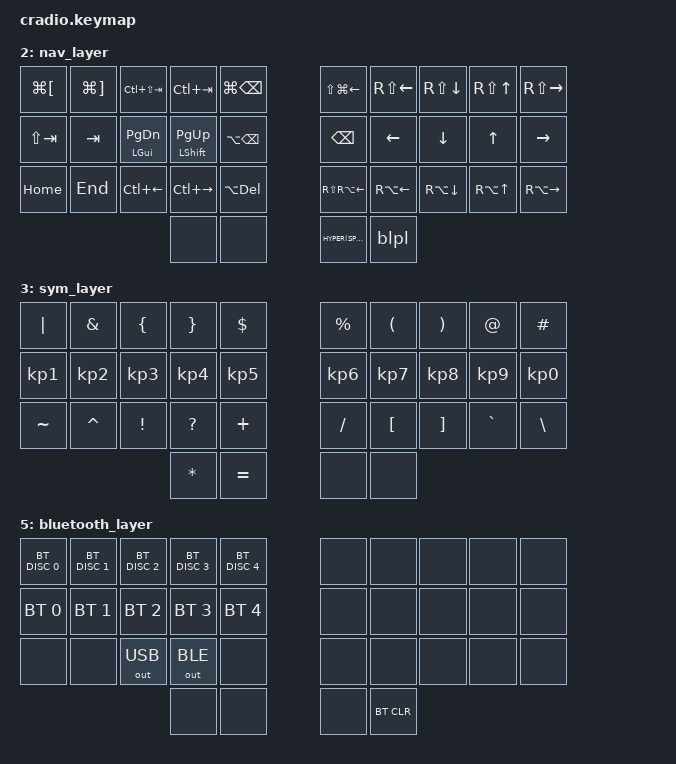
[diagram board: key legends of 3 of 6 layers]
#include <behaviors.dtsi>
#include <dt-bindings/zmk/keys.h>
#include <dt-bindings/zmk/bt.h>
#include <dt-bindings/zmk/outputs.h>

// Home row mods macro
#define HRML(k1, k2, k3) &hrm LALT k1  &hrm LGUI k2  &hrm LSHFT k3
#define HRMR(k1, k2, k3) &hrm RSHFT k1  &hrm RGUI k2  &hrm RALT k3
// hyper
#define HYPER(k) &kp RC(RA(RS(RG(k))))

&lt {
	flavor = "hold-preferred";
	quick-tap-ms = <150>;
};

&mt {
	quick-tap-ms = <150>;
};

/ {
	combos {
		compatible = "zmk,combos";
		combo_space_enter_media {
			layers = <0 1 4>;
			slow-release;
			key-positions = <31 32>;
			bindings = <&tog 4>;
		};
		combo_shifts_caps_word {
			layers = <0 1>;
			slow-release;
			key-positions = <13 16>;
			bindings = <&caps_word>;
		};
	};

	macros {
		blpl: base_layer_plus_lang {
			compatible = "zmk,behavior-macro";
			#binding-cells = <0>;
			bindings
				= <&tog 1>
				, <&kp RC(RA(RS(RG(SPACE))))>
				;
		};
	};

	behaviors {
		// on base
		hrm: hold_tap {
			compatible = "zmk,behavior-hold-tap";
			#binding-cells = <2>;
			flavor = "tap-preferred";
			tapping-term-ms = <220>;
			quick-tap-ms = <150>;
			require-prior-idle-ms = <100>;
			bindings = <&kp>, <&kp>;
		};
		lt_kp: hold_layer_tap_key {
			compatible = "zmk,behavior-hold-tap";
			#binding-cells = <2>;
			flavor = "tap-preferred";
			tapping-term-ms = <220>;
			quick-tap-ms = <150>;
			require-prior-idle-ms = <100>;
			bindings = <&mo>, <&kp>;
		};

		// on qwe
		tdpg: tap_dance_p_grave {
			compatible = "zmk,behavior-tap-dance";
			#binding-cells = <0>;
			bindings = <&kp P>, <&kp SQT>;
		};
		tdmlb: tap_dance_m_left_bracket {
			compatible = "zmk,behavior-tap-dance";
			#binding-cells = <0>;
			bindings = <&kp M>, <&kp LBKT>;
		};
		tdcrb: tap_dance_comma_right_bracket {
			compatible = "zmk,behavior-tap-dance";
			#binding-cells = <0>;
			bindings = <&kp COMMA>, <&kp RBKT>;
		};
		tdfsbs: tap_dance_forwardslash_backwardslash {
			compatible = "zmk,behavior-tap-dance";
			#binding-cells = <0>;
			bindings = <&kp SLASH>, <&kp BSLH>;
		};
		tdgmin: tap_dance_g_minus {
			compatible = "zmk,behavior-tap-dance";
			#binding-cells = <0>;
			bindings = <&kp G>, <&kp MINUS>;
		};
	};

	keymap {
		compatible = "zmk,keymap";
		fyou_layer {
			bindings = <
//╭────────────┬──────────┬──────────┬──────────┬───────────────╮   ╭───────────────┬──────────┬──────────┬──────────┬──────────╮
//│K           │Y         │O         │U         │'              │   │Z              │C         │D         │P         │M         │
   &kp K        &kp Y      &kp O      &kp U      &kp SQT             &kp Z           &kp C      &kp D      &kp P      &kp M
//├────────────┼──────────┼──────────┼──────────┼───────────────┤   ├───────────────┼──────────┼──────────┼──────────┼──────────┤
//│            │          │          │caps word+│               │   │               │+caps word│          │          │          │ combo
//│            │OPT       │CMD       │SHIFT     │               │   │               │SHIFT     │CMD       │OPT       │          │ hold
//│H           │I         │E         │A         │-              │   │G              │S         │T         │N         │L         │
   &kp H   HRML(I,         E,         A)         &kp MINUS           &kp G      HRMR(S,         T,         N)         &kp L
//├────────────┼──────────┼──────────┼──────────┼───────────────┤   ├───────────────┼──────────┼──────────┼──────────┼──────────┤
//│J           │Q         │,         │.         │;              │   │X              │W         │B         │F         │V         │
   &kp J        &kp Q      &kp COMMA  &kp DOT    &kp SEMI            &kp X           &kp W      &kp B      &kp F      &kp V
//╰────────────┴──────────┴──────────┼──────────┼───────────────┤   ├───────────────┼──────────┼──────────┴──────────┴──────────╯
//                                   │          │               MEDIA               │          │                                  combo
//                                   │NAV       │               │   │               │SYM       │                                  hold layer
//                                   │ESC       │SPACE          │   │ENTER          │R         │
								  	  &lt 2 ESC  &mt LCTRL SPACE     &mt RCTRL ENTER &lt_kp 3 R
//                                   ╰──────────┴───────────────╯   ╰───────────────┴──────────╯
			>;
		};

		qwerty_layer {
			bindings = <
//╭───────────┬──────────┬──────────┬──────────┬──────────╮   ╭───────────┬──────────┬──────────┬──────────┬──────────╮
//│           │          │          │          │          │   │           │          │          │          │P '       │ tap dance
//│Q          │W         │E         │R         │T         │   │Y          │U         │I         │O         │          │
   &kp Q       &kp W      &kp E      &kp R      &kp T          &kp Y       &kp U      &kp I      &kp O      &tdpg
//├───────────┼──────────┼──────────┼──────────┼──────────┤   ├───────────┼──────────┼──────────┼──────────┼──────────┤
//│           │          │          │          │G -       │   │           │          │          │          │          │ tap dance
//│           │          │          │caps word+│          │   │           │+caps word│          │          │          │ combo
//│           │OPT       │CMD       │SHIFT     │          │   │           │SHIFT     │CMD       │OPT       │          │ hold
//│A          │S         │D         │F         │          │   │H          │J         │K         │L         │;         │
   &kp A  HRML(S,         D,         F)         &tdgmin        &kp H  HRMR(J,         K,         L)         &kp SEMI
//├───────────┼──────────┼──────────┼──────────┼──────────┤   ├───────────┼──────────┼──────────┼──────────┼──────────┤
//│           │          │          │          │          │   │           │M [       │, ]       │          │/ \       │ tap dance
//│Z          │X         │C         │V         │B         │   │N          │          │          │.         │          │
   &kp Z       &kp X      &kp C      &kp V      &kp B          &kp N       &tdmlb     &tdcrb     &kp DOT    &tdfsbs
//╰───────────┴──────────┴──────────┼──────────┼──────────┤   ├───────────┼──────────┼──────────┴──────────┴──────────╯
//                                  │NAV       │          │   │           │SYM       │                                  hold layer
//                                  │ESC       │SPACE     │   │ENTER      │BACKSPACE │
									 &lt 2 ESC  &kp SPACE      &kp ENTER   &lt 3 BSPC
//                                  ╰──────────┴──────────╯   ╰───────────┴──────────╯
			>;
		};

		nav_layer {
			bindings = <
//╭────────────┬────────────┬───────────────┬────────────────┬────────────╮   ╭────────────────┬────────────┬────────────┬──────────┬─────────────╮
//│history back│history forw│prev tab       │next tab        │remove line │   │SHIFT CMD ←     │SHIFT ←     │SHIFT ↓     │SHIFT ↑   │SHIFT →      │
   &kp LG(LBKT) &kp LG(RBKT) &kp LC(LS(TAB)) &kp LC(TAB)      &kp LG(BSPC)     &kp LS(LG(LEFT)) &kp RS(LEFT) &kp RS(DOWN) &kp RS(UP) &kp RS(RIGHT)
//├────────────┼────────────┼───────────────┼────────────────┼────────────┤   ├────────────────┼────────────┼────────────┼──────────┼─────────────┤
//│            │            │CMD            │SHIFT           │            │   │                │            │            │          │             │ hold
//│SHIFT TAB   │TAB         │PAGE DOWN      │PAGE UP         │remove word │   │BACKSPACE       │←           │↓           │↑         │→            │
   &kp LS(TAB)  &kp TAB      &hrm LGUI PG_DN &hrm LSHFT PG_UP &kp LA(BSPC)     &kp BSPC         &kp LEFT     &kp DOWN     &kp UP     &kp RIGHT
//├────────────┼────────────┼───────────────┼────────────────┼────────────┤   ├────────────────┼────────────┼────────────┼──────────┼─────────────┤
//│            │            │prev space     │next space      │delele line │   │SHIFT ALT ←     │ALT ←       │ALT ↓       │ALT ↑     │ALT →        │
   &kp HOME     &kp END      &kp LC(LEFT)    &kp LC(RIGHT)    &kp LA(DEL)      &kp RS(RA(LEFT)) &kp RA(LEFT) &kp RA(DOWN) &kp RA(UP) &kp RA(RIGHT)
//╰────────────┴────────────┴───────────────┼────────────────┼────────────┤   ├────────────────┼────────────┼────────────┴──────────┴─────────────╯
//                                          │                │            │   │LANG            │BASE + LANG │
											 &none            &none            HYPER(SPACE)     &blpl
//                                          ╰────────────────┴────────────╯   ╰────────────────┴────────────╯
			>;
		};

		sym_layer {
			bindings = <
//╭──────────┬──────────┬────────────┬──────────┬──────────╮   ╭──────────┬──────────┬──────────┬──────────┬──────────╮
//│          │          │            │          │          │   │          │          │          │          │          │ tap dance
//│|         │&         │{           │}         │$         │   │%         │(         │)         │@         │#         │
   &kp PIPE   &kp AMPS   &kp LBRC     &kp RBRC   &kp DLLR       &kp PRCNT  &kp LPAR   &kp RPAR   &kp AT     &kp HASH
//├──────────┼──────────┼────────────┼──────────┼──────────┤   ├──────────┼──────────┼──────────┼──────────┼──────────┤
//│1         │2         │3           │4         │5         │   │6         │7         │8         │9         │0         │
   &kp KP_N1  &kp KP_N2  &kp KP_N3    &kp KP_N4  &kp KP_N5      &kp KP_N6  &kp KP_N7  &kp KP_N8  &kp KP_N9  &kp KP_N0
//├──────────┼──────────┼────────────┼──────────┼──────────┤   ├──────────┼──────────┼──────────┼──────────┼──────────┤
//│~         │^         │!           │?         │+         │   │/         │[         │]         │`         │\         │
   &kp TILDE  &kp CARET  &kp EXCL     &kp QMARK  &kp PLUS       &kp FSLH   &kp LBKT   &kp RBKT   &kp GRAVE  &kp BSLH
//╰──────────┴──────────┴────────────┼──────────┼──────────┤   ├──────────┼──────────┼──────────┴──────────┴──────────╯
//                                   │*         │=         │   │          │          │
									  &kp STAR   &kp EQUAL      &none      &none
//                                   ╰──────────┴──────────╯   ╰──────────┴──────────╯
			>;
		};

		media_layer {
			bindings = <
//╭─────────────┬──────────┬──────────────┬──────────────┬──────────────────╮   ╭──────────┬──────────┬────────────┬────────────┬──────────╮
//│web inspector│          │video capture │screen to file│screen to buffer  │   │ESC       │pause/play│mute        │            │BT        │
   &kp LA(LG(I)) &none      &kp LS(LG(N5)) &kp LS(LG(N4)) &kp LC(LS(LG(N4)))     &kp ESC    &kp C_PP   &kp C_MUTE   &none        &mo 5
//├─────────────┼──────────┼──────────────┼──────────────┼──────────────────┤   ├──────────┼──────────┼────────────┼────────────┼──────────┤
//│             │          │brightness ↓  │brightness ↑  │copy              │   │BACKSPACE │prev track│volume ↓    │volume ↑    │next track│
   &none         &none      &kp C_BRI_DN   &kp C_BRI_UP   &kp LG(C)              &kp BSPC   &kp C_PREV &kp C_VOL_DN &kp C_VOL_UP &kp C_NEXT
//├─────────────┼──────────┼──────────────┼──────────────┼──────────────────┤   ├──────────┼──────────┼────────────┼────────────┼──────────┤
//│←            │↓         │↑             │→             │paste             │   │          │←         │↓           │↑           │→         │
   &kp LEFT      &kp DOWN   &kp UP         &kp RIGHT      &kp LG(V)              &none      &kp LEFT   &kp DOWN     &kp UP       &kp RIGHT
//╰─────────────┴──────────┴──────────────┼──────────────┼──────────────────┤   ├──────────┼──────────┼────────────┴────────────┴──────────╯
//                                        │MEDIA         │SPACE             │   │ENTER     │MEDIA     │
										   &tog 4         &kp SPACE              &kp ENTER  &tog 4
//                                        ╰──────────────┴──────────────────╯   ╰──────────┴──────────╯
			>;
		};

		bluetooth_layer {
			bindings = <
//╭─────────────┬─────────────┬─────────────┬─────────────┬─────────────╮   ╭──────────┬─────────────┬──────────┬──────────┬──────────╮
//│bt 1 off     │bt 2 off     │bt 3 off     │bt 4 off     │bt 5 off     │   │          │             │          │          │          │
   &bt BT_DISC 0 &bt BT_DISC 1 &bt BT_DISC 2 &bt BT_DISC 3 &bt BT_DISC 4     &none      &none         &none      &none      &none
//├─────────────┼─────────────┼─────────────┼─────────────┼─────────────┤   ├──────────┼─────────────┼──────────┼──────────┼──────────┤
//│bt 1 on      │bt 2 on      │bt 3 on      │bt 4 on      │bt 5 on      │   │          │             │          │          │          │
   &bt BT_SEL 0  &bt BT_SEL 1  &bt BT_SEL 2  &bt BT_SEL 3  &bt BT_SEL 4      &none      &none         &none      &none      &none
//├─────────────┼─────────────┼─────────────┼─────────────┼─────────────┤   ├──────────┼─────────────┼──────────┼──────────┼──────────┤
//│             │             │prefer usb   │prefer ble   │             │   │          │             │          │          │          │
   &none         &none         &out OUT_USB  &out OUT_BLE  &none             &none      &none         &none      &none      &none
//╰─────────────┴─────────────┴─────────────┼─────────────┼─────────────┤   ├──────────┼─────────────┼──────────┴──────────┴──────────╯
//                                          │             │             │   │          │clear current│
											 &none         &none             &none      &bt BT_CLR
//                                          ╰─────────────┴─────────────╯   ╰──────────┴─────────────╯
			>;
		};
	};
};
